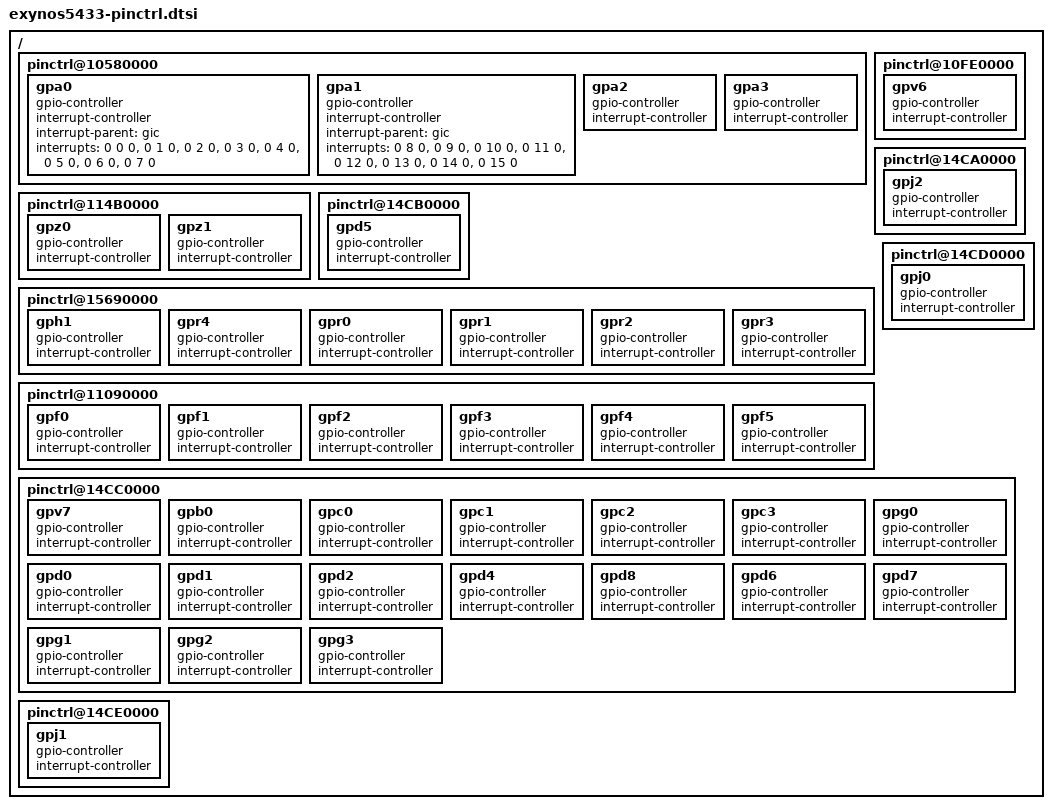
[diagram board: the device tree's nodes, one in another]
/*
 * Samsung's Exynos5433 SoC pin-mux and pin-config device tree source
 *
 * Copyright (c) 2013 Samsung Electronics Co., Ltd.
 *		http://www.samsung.com
 *
 * Samsung's Exynos5433 SoC pin-mux and pin-config options are listed as device
 * tree nodes are listed in this file.
 *
 * This program is free software; you can redistribute it and/or modify
 * it under the terms of the GNU General Public License version 2 as
 * published by the Free Software Foundation.
*/

/ {
	pinctrl@10580000 {
		gpa0: gpa0 {
			gpio-controller;
			#gpio-cells = <2>;

			interrupt-controller;
			#interrupt-cells = <3>;
			interrupt-parent = <&gic>;
			interrupts = <0 0 0>, <0 1 0>, <0 2 0>, <0 3 0>,
				     <0 4 0>, <0 5 0>, <0 6 0>, <0 7 0>;
		};

		gpa1: gpa1 {
			gpio-controller;
			#gpio-cells = <2>;

			interrupt-controller;
			#interrupt-cells = <3>;
			interrupt-parent = <&gic>;
			interrupts = <0 8 0>, <0 9 0>, <0 10 0>, <0 11 0>,
				     <0 12 0>, <0 13 0>, <0 14 0>, <0 15 0>;
		};

		gpa2: gpa2 {
			gpio-controller;
			#gpio-cells = <2>;

			interrupt-controller;
			#interrupt-cells = <2>;
		};

		gpa3: gpa3 {
			gpio-controller;
			#gpio-cells = <2>;

			interrupt-controller;
			#interrupt-cells = <2>;
		};
	};

	pinctrl@114B0000 {
		gpz0: gpz0 {
			gpio-controller;
			#gpio-cells = <2>;

			interrupt-controller;
			#interrupt-cells = <2>;
		};

		gpz1: gpz1 {
			gpio-controller;
			#gpio-cells = <2>;

			interrupt-controller;
			#interrupt-cells = <2>;
		};
	};

	pinctrl@10FE0000 {
		gpv6: gpv6 {
			gpio-controller;
			#gpio-cells = <2>;

			interrupt-controller;
			#interrupt-cells = <2>;
		};
	};

	pinctrl@14CA0000 {
		gpj2: gpj2 {
			gpio-controller;
			#gpio-cells = <2>;

			interrupt-controller;
			#interrupt-cells = <2>;
		};
	};

	pinctrl@14CB0000 {
		gpd5: gpd5 {
			gpio-controller;
			#gpio-cells = <2>;

			interrupt-controller;
			#interrupt-cells = <2>;
		};
	};

	pinctrl@15690000 {
		gph1: gph1 {
			gpio-controller;
			#gpio-cells = <2>;

			interrupt-controller;
			#interrupt-cells = <2>;
		};

		gpr4: gpr4 {
			gpio-controller;
			#gpio-cells = <2>;

			interrupt-controller;
			#interrupt-cells = <2>;
		};

		gpr0: gpr0 {
			gpio-controller;
			#gpio-cells = <2>;

			interrupt-controller;
			#interrupt-cells = <2>;
		};

		gpr1: gpr1 {
			gpio-controller;
			#gpio-cells = <2>;

			interrupt-controller;
			#interrupt-cells = <2>;
		};

		gpr2: gpr2 {
			gpio-controller;
			#gpio-cells = <2>;

			interrupt-controller;
			#interrupt-cells = <2>;
		};

		gpr3: gpr3 {
			gpio-controller;
			#gpio-cells = <2>;

			interrupt-controller;
			#interrupt-cells = <2>;
		};
	};

	pinctrl@11090000 {
		gpf0: gpf0 {
			gpio-controller;
			#gpio-cells = <2>;

			interrupt-controller;
			#interrupt-cells = <2>;
		};

		gpf1: gpf1 {
			gpio-controller;
			#gpio-cells = <2>;

			interrupt-controller;
			#interrupt-cells = <2>;
		};

		gpf2: gpf2 {
			gpio-controller;
			#gpio-cells = <2>;

			interrupt-controller;
			#interrupt-cells = <2>;
		};

		gpf3: gpf3 {
			gpio-controller;
			#gpio-cells = <2>;

			interrupt-controller;
			#interrupt-cells = <2>;
		};

		gpf4: gpf4 {
			gpio-controller;
			#gpio-cells = <2>;

			interrupt-controller;
			#interrupt-cells = <2>;
		};

		gpf5: gpf5 {
			gpio-controller;
			#gpio-cells = <2>;

			interrupt-controller;
			#interrupt-cells = <2>;
		};
	};

	pinctrl@14CD0000 {
		gpj0: gpj0 {
			gpio-controller;
			#gpio-cells = <2>;

			interrupt-controller;
			#interrupt-cells = <2>;
		};
	};

	pinctrl@14CC0000 {
		gpv7: gpv7 {
			gpio-controller;
			#gpio-cells = <2>;

			interrupt-controller;
			#interrupt-cells = <2>;
		};

		gpb0: gpb0 {
			gpio-controller;
			#gpio-cells = <2>;

			interrupt-controller;
			#interrupt-cells = <2>;
		};

		gpc0: gpc0 {
			gpio-controller;
			#gpio-cells = <2>;

			interrupt-controller;
			#interrupt-cells = <2>;
		};

		gpc1: gpc1 {
			gpio-controller;
			#gpio-cells = <2>;

			interrupt-controller;
			#interrupt-cells = <2>;
		};

		gpc2: gpc2 {
			gpio-controller;
			#gpio-cells = <2>;

			interrupt-controller;
			#interrupt-cells = <2>;
		};

		gpc3: gpc3 {
			gpio-controller;
			#gpio-cells = <2>;

			interrupt-controller;
			#interrupt-cells = <2>;
		};

		gpg0: gpg0 {
			gpio-controller;
			#gpio-cells = <2>;

			interrupt-controller;
			#interrupt-cells = <2>;
		};

		gpd0: gpd0 {
			gpio-controller;
			#gpio-cells = <2>;

			interrupt-controller;
			#interrupt-cells = <2>;
		};

		gpd1: gpd1 {
			gpio-controller;
			#gpio-cells = <2>;

			interrupt-controller;
			#interrupt-cells = <2>;
		};

		gpd2: gpd2 {
			gpio-controller;
			#gpio-cells = <2>;

			interrupt-controller;
			#interrupt-cells = <2>;
		};

		gpd4: gpd4 {
			gpio-controller;
			#gpio-cells = <2>;

			interrupt-controller;
			#interrupt-cells = <2>;
		};

		gpd8: gpd8 {
			gpio-controller;
			#gpio-cells = <2>;

			interrupt-controller;
			#interrupt-cells = <2>;
		};

		gpd6: gpd6 {
			gpio-controller;
			#gpio-cells = <2>;

			interrupt-controller;
			#interrupt-cells = <2>;
		};

		gpd7: gpd7 {
			gpio-controller;
			#gpio-cells = <2>;

			interrupt-controller;
			#interrupt-cells = <2>;
		};

		gpg1: gpg1 {
			gpio-controller;
			#gpio-cells = <2>;

			interrupt-controller;
			#interrupt-cells = <2>;
		};

		gpg2: gpg2 {
			gpio-controller;
			#gpio-cells = <2>;

			interrupt-controller;
			#interrupt-cells = <2>;
		};

		gpg3: gpg3 {
			gpio-controller;
			#gpio-cells = <2>;

			interrupt-controller;
			#interrupt-cells = <2>;
		};
	};

	pinctrl@14CE0000 {
		gpj1: gpj1 {
			gpio-controller;
			#gpio-cells = <2>;

			interrupt-controller;
			#interrupt-cells = <2>;
		};
	};
};
